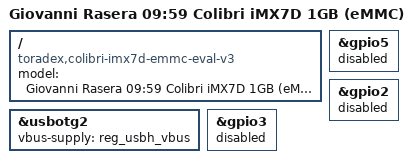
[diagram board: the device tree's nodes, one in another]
// SPDX-License-Identifier: GPL-2.0 OR MIT
/*
 * Copyright 2017-2021 Toradex
 */

/dts-v1/;
#include "imx7d-colibri-emmc.dtsi"
#include "imx7-colibri-eval-v3.dtsi"

/ {
	model = "Giovanni Rasera 09:59 Colibri iMX7D 1GB (eMMC)";
	compatible = "toradex,colibri-imx7d-emmc-eval-v3",
		     "toradex,colibri-imx7d-emmc",
		     "toradex,colibri-imx7d",
		     "fsl,imx7d";
};

&usbotg2 {
	vbus-supply = <&reg_usbh_vbus>;
	status = "okay";
};

&gpio5{
	status = "disabled";
};

&gpio2{
	status = "disabled";
};

&gpio3{
	status = "disabled";
};


